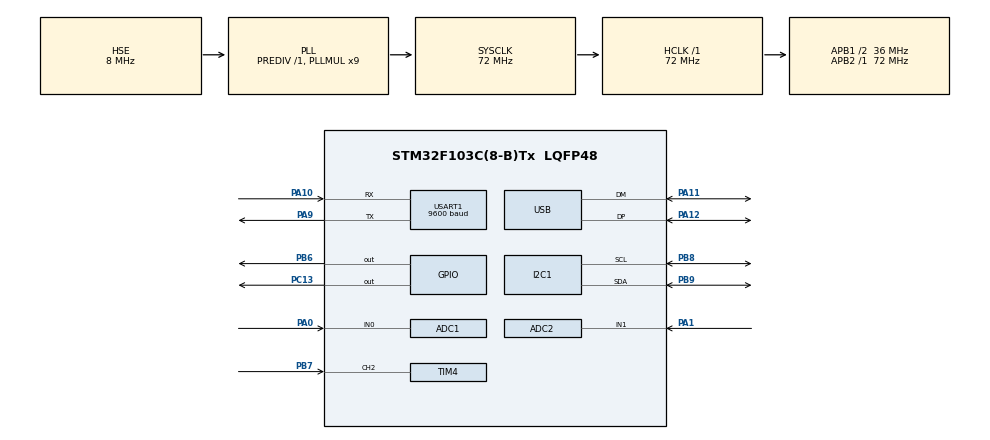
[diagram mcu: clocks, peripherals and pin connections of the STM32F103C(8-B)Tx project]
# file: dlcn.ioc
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ADC1.Channel-0\#ChannelRegularConversion=ADC_CHANNEL_0
ADC1.ContinuousConvMode=ENABLE
ADC1.NbrOfConversionFlag=1
ADC1.Rank-0\#ChannelRegularConversion=1
ADC1.SamplingTime-0\#ChannelRegularConversion=ADC_SAMPLETIME_1CYCLE_5
ADC1.master=1
ADC2.Channel-0\#ChannelRegularConversion=ADC_CHANNEL_1
ADC2.ContinuousConvMode=ENABLE
ADC2.NbrOfConversionFlag=1
ADC2.Rank-0\#ChannelRegularConversion=1
ADC2.SamplingTime-0\#ChannelRegularConversion=ADC_SAMPLETIME_1CYCLE_5
Mcu.Family=STM32F1
Mcu.Name=STM32F103C(8-B)Tx
Mcu.Package=LQFP48
NVIC.PriorityGroup=NVIC_PRIORITYGROUP_4
NVIC.TIM2_IRQn=true\:15\:0\:false\:false\:true\:true\:true\:true
NVIC.USB_LP_CAN1_RX0_IRQn=true\:0\:0\:false\:false\:true\:false\:true\:true
PA0-WKUP.Signal=ADCx_IN0
PA1.Signal=ADCx_IN1
PA10.Mode=Asynchronous
PA10.Signal=USART1_RX
PA11.Mode=Device
PA11.Signal=USB_DM
PA12.Mode=Device
PA12.Signal=USB_DP
PA13.Mode=Serial_Wire
PA13.Signal=SYS_JTMS-SWDIO
PA14.Mode=Serial_Wire
PA14.Signal=SYS_JTCK-SWCLK
PA9.Mode=Asynchronous
PA9.Signal=USART1_TX
PB6.Signal=GPIO_Output
PB7.Signal=S_TIM4_CH2
PB8.Mode=I2C
PB8.Signal=I2C1_SCL
PB9.Mode=I2C
PB9.Signal=I2C1_SDA
PC13-TAMPER-RTC.Signal=GPIO_Output
PD0-OSC_IN.Mode=HSE-External-Oscillator
PD0-OSC_IN.Signal=RCC_OSC_IN
PD1-OSC_OUT.Mode=HSE-External-Oscillator
PD1-OSC_OUT.Signal=RCC_OSC_OUT
ProjectManager.HeapSize=0x200
ProjectManager.StackSize=0x400
ProjectManager.TargetToolchain=STM32CubeIDE
RCC.ADCPresc=RCC_ADCPCLK2_DIV6
RCC.AHBFreq_Value=72000000
RCC.APB1CLKDivider=RCC_HCLK_DIV2
RCC.APB1Freq_Value=36000000
RCC.APB1TimFreq_Value=72000000
RCC.APB2Freq_Value=72000000
RCC.APB2TimFreq_Value=72000000
RCC.HCLKFreq_Value=72000000
RCC.PLLMUL=RCC_PLL_MUL9
RCC.PLLSourceVirtual=RCC_PLLSOURCE_HSE
RCC.SYSCLKFreq_VALUE=72000000
RCC.SYSCLKSource=RCC_SYSCLKSOURCE_PLLCLK
RCC.USBFreq_Value=48000000
RCC.USBPrescaler=RCC_USBCLKSOURCE_PLL_DIV1_5
SH.ADCx_IN0.0=ADC1_IN0,IN0
SH.ADCx_IN1.0=ADC2_IN1,IN1
SH.S_TIM4_CH2.0=TIM4_CH2,Input_Capture2_from_TI2
TIM2.AutoReloadPreload=TIM_AUTORELOAD_PRELOAD_ENABLE
TIM2.Period=99
TIM2.Prescaler=7200-1
TIM4.Channel-Input_Capture2_from_TI2=TIM_CHANNEL_2
USART1.BaudRate=9600
USART1.VirtualMode=VM_ASYNC
USB_DEVICE.APP_RX_DATA_SIZE=64
USB_DEVICE.APP_TX_DATA_SIZE=64
USB_DEVICE.CLASS_NAME_FS=CDC
USB_DEVICE.VirtualMode=Cdc
USB_DEVICE.VirtualModeFS=Cdc_FS
VP_TIM2_VS_ClockSourceINT.Mode=Internal
VP_TIM4_VS_ClockSourceINT.Mode=Internal
VP_USB_DEVICE_VS_USB_DEVICE_CDC_FS.Mode=CDC_FS
board=custom

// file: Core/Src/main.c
/* USER CODE BEGIN Header */
/**
  ******************************************************************************
  * @file           : main.c
  * @brief          : Main program body
  ******************************************************************************
  * @attention
  *
  * Copyright (c) 2026 STMicroelectronics.
  * All rights reserved.
  *
  * This software is licensed under terms that can be found in the LICENSE file
  * in the root directory of this software component.
  * If no LICENSE file comes with this software, it is provided AS-IS.
  *
  ******************************************************************************
  */
/* USER CODE END Header */
#include "main.h"
#include "usb_device.h"

ADC_HandleTypeDef hadc1;
ADC_HandleTypeDef hadc2;

I2C_HandleTypeDef hi2c1;

TIM_HandleTypeDef htim2;
TIM_HandleTypeDef htim4;

UART_HandleTypeDef huart1;

void SystemClock_Config(void);
static void MX_GPIO_Init(void);
static void MX_ADC1_Init(void);
static void MX_ADC2_Init(void);
static void MX_I2C1_Init(void);
static void MX_TIM2_Init(void);
static void MX_TIM4_Init(void);
static void MX_USART1_UART_Init(void);

/* USER CODE BEGIN 0 */
uint8_t dem=0;
/* USER CODE END 0 */

int main(void)
{

  /* MCU Configuration--------------------------------------------------------*/

  /* Reset of all peripherals, Initializes the Flash interface and the Systick. */
  HAL_Init();

  /* Configure the system clock */
  SystemClock_Config();

  /* Initialize all configured peripherals */
  MX_GPIO_Init();
  MX_ADC1_Init();
  MX_ADC2_Init();
  MX_I2C1_Init();
  MX_TIM2_Init();
  MX_TIM4_Init();
  MX_USB_DEVICE_Init();
  MX_USART1_UART_Init();
  /* USER CODE BEGIN 2 */
  HAL_TIM_Base_Start_IT(&htim4);
  /* USER CODE END 2 */

  /* Infinite loop */
  while (1)
  {

  }
}

void SystemClock_Config(void)
{
  RCC_OscInitTypeDef RCC_OscInitStruct = {0};
  RCC_ClkInitTypeDef RCC_ClkInitStruct = {0};
  RCC_PeriphCLKInitTypeDef PeriphClkInit = {0};

  /** Initializes the RCC Oscillators according to the specified parameters
  * in the RCC_OscInitTypeDef structure.
  */
  RCC_OscInitStruct.OscillatorType = RCC_OSCILLATORTYPE_HSE;
  RCC_OscInitStruct.HSEState = RCC_HSE_ON;
  RCC_OscInitStruct.HSEPredivValue = RCC_HSE_PREDIV_DIV1;
  RCC_OscInitStruct.HSIState = RCC_HSI_ON;
  RCC_OscInitStruct.PLL.PLLState = RCC_PLL_ON;
  RCC_OscInitStruct.PLL.PLLSource = RCC_PLLSOURCE_HSE;
  RCC_OscInitStruct.PLL.PLLMUL = RCC_PLL_MUL9;
  if (HAL_RCC_OscConfig(&RCC_OscInitStruct) != HAL_OK)
  {
    Error_Handler();
  }

  /** Initializes the CPU, AHB and APB buses clocks
  */
  RCC_ClkInitStruct.ClockType = RCC_CLOCKTYPE_HCLK|RCC_CLOCKTYPE_SYSCLK
                              |RCC_CLOCKTYPE_PCLK1|RCC_CLOCKTYPE_PCLK2;
  RCC_ClkInitStruct.SYSCLKSource = RCC_SYSCLKSOURCE_PLLCLK;
  RCC_ClkInitStruct.AHBCLKDivider = RCC_SYSCLK_DIV1;
  RCC_ClkInitStruct.APB1CLKDivider = RCC_HCLK_DIV2;
  RCC_ClkInitStruct.APB2CLKDivider = RCC_HCLK_DIV1;

  if (HAL_RCC_ClockConfig(&RCC_ClkInitStruct, FLASH_LATENCY_2) != HAL_OK)
  {
    Error_Handler();
  }
  PeriphClkInit.PeriphClockSelection = RCC_PERIPHCLK_ADC|RCC_PERIPHCLK_USB;
  PeriphClkInit.AdcClockSelection = RCC_ADCPCLK2_DIV6;
  PeriphClkInit.UsbClockSelection = RCC_USBCLKSOURCE_PLL_DIV1_5;
  if (HAL_RCCEx_PeriphCLKConfig(&PeriphClkInit) != HAL_OK)
  {
    Error_Handler();
  }
}

static void MX_ADC1_Init(void)
{

  ADC_ChannelConfTypeDef sConfig = {0};

  /** Common config
  */
  hadc1.Instance = ADC1;
  hadc1.Init.ScanConvMode = ADC_SCAN_DISABLE;
  hadc1.Init.ContinuousConvMode = ENABLE;
  hadc1.Init.DiscontinuousConvMode = DISABLE;
  hadc1.Init.ExternalTrigConv = ADC_SOFTWARE_START;
  hadc1.Init.DataAlign = ADC_DATAALIGN_RIGHT;
  hadc1.Init.NbrOfConversion = 1;
  if (HAL_ADC_Init(&hadc1) != HAL_OK)
  {
    Error_Handler();
  }

  /** Configure Regular Channel
  */
  sConfig.Channel = ADC_CHANNEL_0;
  sConfig.Rank = ADC_REGULAR_RANK_1;
  sConfig.SamplingTime = ADC_SAMPLETIME_1CYCLE_5;
  if (HAL_ADC_ConfigChannel(&hadc1, &sConfig) != HAL_OK)
  {
    Error_Handler();
  }

}

static void MX_ADC2_Init(void)
{

  ADC_ChannelConfTypeDef sConfig = {0};

  /** Common config
  */
  hadc2.Instance = ADC2;
  hadc2.Init.ScanConvMode = ADC_SCAN_DISABLE;
  hadc2.Init.ContinuousConvMode = ENABLE;
  hadc2.Init.DiscontinuousConvMode = DISABLE;
  hadc2.Init.ExternalTrigConv = ADC_SOFTWARE_START;
  hadc2.Init.DataAlign = ADC_DATAALIGN_RIGHT;
  hadc2.Init.NbrOfConversion = 1;
  if (HAL_ADC_Init(&hadc2) != HAL_OK)
  {
    Error_Handler();
  }

  /** Configure Regular Channel
  */
  sConfig.Channel = ADC_CHANNEL_1;
  sConfig.Rank = ADC_REGULAR_RANK_1;
  sConfig.SamplingTime = ADC_SAMPLETIME_1CYCLE_5;
  if (HAL_ADC_ConfigChannel(&hadc2, &sConfig) != HAL_OK)
  {
    Error_Handler();
  }

}

static void MX_I2C1_Init(void)
{

  hi2c1.Instance = I2C1;
  hi2c1.Init.ClockSpeed = 100000;
  hi2c1.Init.DutyCycle = I2C_DUTYCYCLE_2;
  hi2c1.Init.OwnAddress1 = 0;
  hi2c1.Init.AddressingMode = I2C_ADDRESSINGMODE_7BIT;
  hi2c1.Init.DualAddressMode = I2C_DUALADDRESS_DISABLE;
  hi2c1.Init.OwnAddress2 = 0;
  hi2c1.Init.GeneralCallMode = I2C_GENERALCALL_DISABLE;
  hi2c1.Init.NoStretchMode = I2C_NOSTRETCH_DISABLE;
  if (HAL_I2C_Init(&hi2c1) != HAL_OK)
  {
    Error_Handler();
  }

}

static void MX_TIM2_Init(void)
{

  TIM_ClockConfigTypeDef sClockSourceConfig = {0};
  TIM_MasterConfigTypeDef sMasterConfig = {0};

  htim2.Instance = TIM2;
  htim2.Init.Prescaler = 7200-1;
  htim2.Init.CounterMode = TIM_COUNTERMODE_UP;
  htim2.Init.Period = 99;
  htim2.Init.ClockDivision = TIM_CLOCKDIVISION_DIV1;
  htim2.Init.AutoReloadPreload = TIM_AUTORELOAD_PRELOAD_ENABLE;
  if (HAL_TIM_Base_Init(&htim2) != HAL_OK)
  {
    Error_Handler();
  }
  sClockSourceConfig.ClockSource = TIM_CLOCKSOURCE_INTERNAL;
  if (HAL_TIM_ConfigClockSource(&htim2, &sClockSourceConfig) != HAL_OK)
  {
    Error_Handler();
  }
  sMasterConfig.MasterOutputTrigger = TIM_TRGO_RESET;
  sMasterConfig.MasterSlaveMode = TIM_MASTERSLAVEMODE_DISABLE;
  if (HAL_TIMEx_MasterConfigSynchronization(&htim2, &sMasterConfig) != HAL_OK)
  {
    Error_Handler();
  }

}

static void MX_TIM4_Init(void)
{

  TIM_ClockConfigTypeDef sClockSourceConfig = {0};
  TIM_MasterConfigTypeDef sMasterConfig = {0};
  TIM_IC_InitTypeDef sConfigIC = {0};

  htim4.Instance = TIM4;
  htim4.Init.Prescaler = 0;
  htim4.Init.CounterMode = TIM_COUNTERMODE_UP;
  htim4.Init.Period = 65535;
  htim4.Init.ClockDivision = TIM_CLOCKDIVISION_DIV1;
  htim4.Init.AutoReloadPreload = TIM_AUTORELOAD_PRELOAD_DISABLE;
  if (HAL_TIM_Base_Init(&htim4) != HAL_OK)
  {
    Error_Handler();
  }
  sClockSourceConfig.ClockSource = TIM_CLOCKSOURCE_INTERNAL;
  if (HAL_TIM_ConfigClockSource(&htim4, &sClockSourceConfig) != HAL_OK)
  {
    Error_Handler();
  }
  if (HAL_TIM_IC_Init(&htim4) != HAL_OK)
  {
    Error_Handler();
  }
  sMasterConfig.MasterOutputTrigger = TIM_TRGO_RESET;
  sMasterConfig.MasterSlaveMode = TIM_MASTERSLAVEMODE_DISABLE;
  if (HAL_TIMEx_MasterConfigSynchronization(&htim4, &sMasterConfig) != HAL_OK)
  {
    Error_Handler();
  }
  sConfigIC.ICPolarity = TIM_INPUTCHANNELPOLARITY_RISING;
  sConfigIC.ICSelection = TIM_ICSELECTION_DIRECTTI;
  sConfigIC.ICPrescaler = TIM_ICPSC_DIV1;
  sConfigIC.ICFilter = 0;
  if (HAL_TIM_IC_ConfigChannel(&htim4, &sConfigIC, TIM_CHANNEL_2) != HAL_OK)
  {
    Error_Handler();
  }

}

static void MX_USART1_UART_Init(void)
{

  huart1.Instance = USART1;
  huart1.Init.BaudRate = 9600;
  huart1.Init.WordLength = UART_WORDLENGTH_8B;
  huart1.Init.StopBits = UART_STOPBITS_1;
  huart1.Init.Parity = UART_PARITY_NONE;
  huart1.Init.Mode = UART_MODE_TX_RX;
  huart1.Init.HwFlowCtl = UART_HWCONTROL_NONE;
  huart1.Init.OverSampling = UART_OVERSAMPLING_16;
  if (HAL_UART_Init(&huart1) != HAL_OK)
  {
    Error_Handler();
  }

}

static void MX_GPIO_Init(void)
{
  GPIO_InitTypeDef GPIO_InitStruct = {0};

  /* GPIO Ports Clock Enable */
  __HAL_RCC_GPIOC_CLK_ENABLE();
  __HAL_RCC_GPIOD_CLK_ENABLE();
  __HAL_RCC_GPIOA_CLK_ENABLE();
  __HAL_RCC_GPIOB_CLK_ENABLE();

  /*Configure GPIO pin Output Level */
  HAL_GPIO_WritePin(GPIOC, GPIO_PIN_13, GPIO_PIN_RESET);

  /*Configure GPIO pin Output Level */
  HAL_GPIO_WritePin(GPIOB, GPIO_PIN_6, GPIO_PIN_RESET);

  /*Configure GPIO pin : PC13 */
  GPIO_InitStruct.Pin = GPIO_PIN_13;
  GPIO_InitStruct.Mode = GPIO_MODE_OUTPUT_PP;
  GPIO_InitStruct.Pull = GPIO_NOPULL;
  GPIO_InitStruct.Speed = GPIO_SPEED_FREQ_LOW;
  HAL_GPIO_Init(GPIOC, &GPIO_InitStruct);

  /*Configure GPIO pin : PB6 */
  GPIO_InitStruct.Pin = GPIO_PIN_6;
  GPIO_InitStruct.Mode = GPIO_MODE_OUTPUT_PP;
  GPIO_InitStruct.Pull = GPIO_NOPULL;
  GPIO_InitStruct.Speed = GPIO_SPEED_FREQ_LOW;
  HAL_GPIO_Init(GPIOB, &GPIO_InitStruct);

}

/* USER CODE BEGIN 4 */
void HAL_TIM_PeriodElapsedCallback(TIM_HandleTypeDef *htim)
{
	if (htim->Instance == TIM1)
	  {
          dem++;
	      HAL_GPIO_TogglePin(GPIOC, GPIO_PIN_13);
	      if(dem%5==0){
	    	 HAL_GPIO_TogglePin(GPIOA, GPIO_PIN_0);
	      }
	      if(dem==10){
	    	 dem=0;
	      	 HAL_GPIO_TogglePin(GPIOA, GPIO_PIN_1);
	      }
	  }
}
/* USER CODE END 4 */

void Error_Handler(void)
{
  __disable_irq();
  while (1)
  {
  }
}
